# PIC32MZ1025DAG176 device description
Architecture: MIPS; Family: PIC32MZDA; Series: PIC32MZ
Registers are 32-bit, read-write, no defined reset value unless marked. A register's access mark holds for its fields unless they carry their own. Offsets are from the block's base; [hi:lo] are bit positions; {n}, {i} and the like mark numbered series; 'fields as' and 'values as' point back to an identical list.

## USB
Instances: USB 0x1f8e3000 in periph_indep
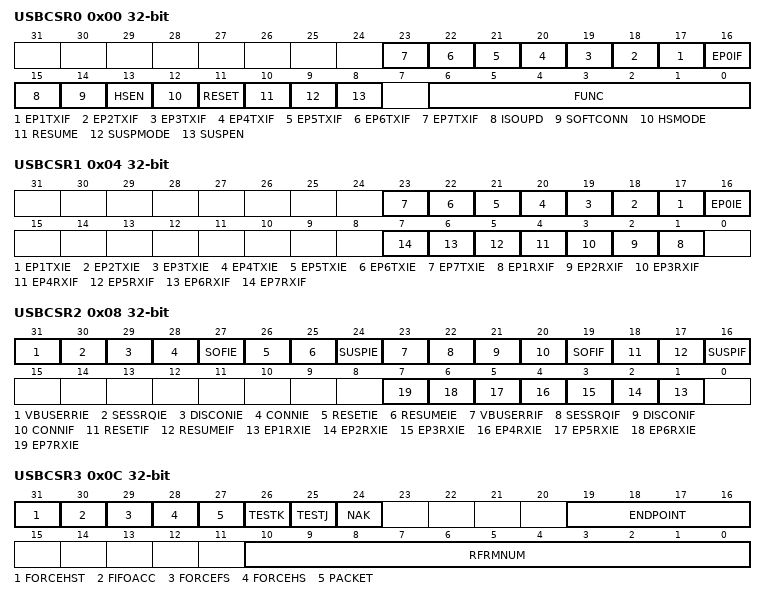
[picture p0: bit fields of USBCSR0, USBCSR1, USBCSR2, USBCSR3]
0x00 USBCSR0 — USB Control Status Register 0
  [n+16] EP{n}TXIF (n=1..7) — Endpoint {n} TX Interrupt Flag bit
    1=Endpoint has a transmit interrupt to be serviced; 0=No interrupt event
  [16] EP0IF — Endpoint 0 Interrupt bit
    1=Endpoint 0 has an interrupt to be serviced; 0=No interrupt event
  [15] ISOUPD — ISO Update bit (
    1=USB module will wait for a SOF token from the time TXPKTRDY is set before sending the packet; 0=No change in behavior
  [14] SOFTCONN — Soft Connect/Disconnect Feature Selection bit
    1=The USB D+/D- lines are enabled and active; 0=The USB D+/D- lines are disabled and are tri-stated
  [13] HSEN — Hi-Speed Enable bit
    1=The USB module will negotiate for Hi-Speed mode when the device is reset by the hub; 0=Module only operates in Full-Speed mode
  [12] HSMODE — Hi-Speed Mode Status bit
    1=Hi-Speed mode successfully negotiated during USB reset; 0=Module is not in Hi-Speed mode
  [11] RESET — Module Reset Status bit
    1=Reset signaling is present on the bus; 0=Normal module operation
  [10] RESUME — Resume from Suspend control bit
    1=Generate Resume signaling when the device is in Suspend mode; 0=Stop Resume signaling
  [9] SUSPMODE — Suspend Mode status bit
    1=The USB module is in Suspend mode; 0=The USB module is in Normal operations
  [8] SUSPEN — Suspend Mode Enable bit
    1=Suspend mode is enabled; 0=Suspend mode is not enabled
  [6:0] FUNC
0x04 USBCSR1 — USB Control Status Register 1
  [n+16] EP{n}TXIE (n=1..7) — Endpoint {n} Transmit Interrupt Enable bits
    1=Endpoint Transmit interrupt events are enabled; 0=Endpoint Transmit interrupt events are not enabled
  [16] EP0IE — Endpoint 0 Interrupt Enable bit
    1=Endpoint 0 interrupt events are enabled; 0=Endpoint 0 interrupt events are not enabled
  [n] EP{n}RXIF (n=1..7) — Endpoint {n} RX Interrupt bit
    1=Endpoint has a receive event to be serviced; 0=No interrupt event
0x08 USBCSR2 — USB Control Status Register 2
  [31] VBUSERRIE — Vbus Error Interrupt Enable bit
    1=Vbus error interrupt is enabled; 0=Vbus error interrupt is disabled
  [30] SESSRQIE — Session Request Interrupt Enable bit
    1=Session request interrupt is enabled; 0=Session request interrupt is disabled
  [29] DISCONIE — Device Disconnect Interrupt Enable bit
    1=Device disconnect interrupt is enabled; 0=Device disconnect interrupt is disabled
  [28] CONNIE — Device Connection Interrupt Enable bit
    1=Device connection interrupt is enabled; 0=Device connection interrupt is disabled
  [27] SOFIE — Start of Frame Interrupt Enable bit
    1=Start of Frame event interrupt is enabled; 0=Start of Frame event interrupt is disabled
  [26] RESETIE — Reset/Babble Interrupt Enable bit
    1=Interrupt when reset (; 0=Reset/Babble interrupt is disabled
  [25] RESUMEIE — Resume Interrupt Enable bit
    1=Resume signaling interrupt is enabled; 0=Resume signaling interrupt is disabled
  [24] SUSPIE — Suspend Interrupt Enable bit
    1=Suspend signaling interrupt is enabled; 0=Suspend signaling interrupt is disabled
  [23] VBUSERRIF — Vbus Error Interrupt bit
    1=Vbus has dropped below the Vbus valid threshold during a session; 0=No interrupt
  [22] SESSRQIF — Session Request Interrupt bit
    1=Session request signaling has been detected; 0=No session request detected
  [21] DISCONIF — Device Disconnect Interrupt bit
    1=In Host mode; 0=No device disconnect detected
  [20] CONNIF — Device Connection Interrupt bit
    1=In Host mode; 0=No device connection detected
  [19] SOFIF — Start of Frame Interrupt bit
    1=A new frame has started; 0=No start of frame detected
  [18] RESETIF — Reset/Babble Interrupt bit
    1=(In Host mode): indicates babble is detected / (In Device mode): indicates reset signaling is detected on the bus; 0=No reset/babble detected
  [17] RESUMEIF — Resume Interrupt bit
    1=Resume signaling is detected on the bus while USB module is in Suspend mode; 0=No Resume signaling detected
  [16] SUSPIF — Suspend Interrupt bit
    1=Suspend signaling is detected on the bus (Device mode); 0=No suspend signaling detected
  [n] EP{n}RXIE (n=1..7) — Endpoint {n} Receive Interrupt Enable bit
    1=Receive interrupt is enabled for this endpoint; 0=Receive interrupt is not enabled
0x0C USBCSR3 — USB Control Status Register 3
  [31] FORCEHST — Test Mode Force Host Select bit
    1=Forces USB module into Host mode; 0=Normal operation
  [30] FIFOACC — Test Mode Endpoint 0 FIFO Transfer Force bit
    1=Transfers the packet in the Endpoint 0 TX FIFO to the Endpoint 0 RX FIFO; 0=No transfer
  [29] FORCEFS — Test mode Force Full-Speed Mode Select bit
    1=Forces USB module into Full-Speed mode. Undefined behavior if FORCEHS is 1; 0=(If FORCEHS is 0): places USB module into Low-Speed mode
  [28] FORCEHS — Test mode Force Hi-Speed Mode Select bit
    1=Forces USB module into Hi-Speed mode. Undefined behavior if FORCEFS = 1.; 0=If FORCEFS is 0
  [27] PACKET — Test_Packet Test Mode Select bit
    1=The USB module repetitively transmits on the bus a 53-byte test packet. Test packet must be loaded into the Endpoint 0 FIFO before the test mode is entered.; 0=Normal operation
  [26] TESTK — Test_K Test Mode Select bit
    1=Enters Test_K test mode. The USB module transmits a continuous K on the bus.; 0=Normal operation
  [25] TESTJ — Test_J Test Mode Select bit
    1=Enters Test_J test mode. The USB module transmits a continuous J on the bus.; 0=Normal operation
  [24] NAK — Test_SE0_NAK Test Mode Select bit
    1=Enter Test_SE0_NAK test mode. The USB module remains in Hi-Speed mode but responds to any valid IN token with a NAK; 0=Normal operation
  [19:16] ENDPOINT — Endpoint Registers Select bits
    {v}=Endpoint {v} (v=0..7)
  [10:0] RFRMNUM
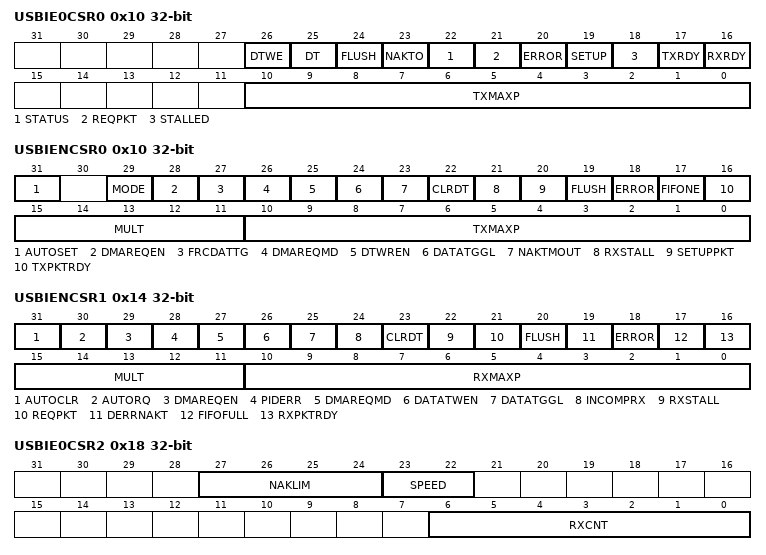
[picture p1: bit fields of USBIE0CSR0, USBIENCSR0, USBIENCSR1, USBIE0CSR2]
0x10 USBIE0CSR0 — USB Indexed Endpoint Control Status Register 0 (Endpoint 0)
  [26] DTWE, [25] DT, [24] FLUSH, [23] NAKTO, [22] STATUS, [21] REQPKT, [20] ERROR, [19] SETUP, [18] STALLED, [17] TXRDY, [16] RXRDY, [10:0] TXMAXP
0x10 USBIENCSR0 — USB Indexed Endpoint Control Status Register 0 (Endpoint 1-7)
  [31] AUTOSET — Auto Set Control bit
    1=TXPKTRDY will be automatically set when data of the maximum packet size (value in TXMAXP) is loaded into the TX FIFO. If a packet of less than the maximum packet size is loaded; 0=TXPKTRDY must be set manually for all packet sizes
  [29] MODE — Endpoint Direction Control bit
    1=Endpoint is TX; 0=Endpoint is RX
  [28] DMAREQEN — Endpoint DMA Request Enable bit
    1=DMA requests are enabled for this endpoint; 0=DMA requests are disabled for this endpoint
  [27] FRCDATTG — Force Endpoint Data Toggle Control bit
    1=Forces the endpoint data toggle to switch and the data packet to be cleared from the FIFO; 0=No forced behavior
  [26] DMAREQMD — Endpoint DMA Request Mode Control bit
    1=DMA Request Mode 1; 0=DMA Request Mode 0
  [25] DTWREN
  [24] DATATGGL
  [23] NAKTMOUT — Incomplete TX Status bit
    1=Meaning of bitfield depends on Host / Device mode of operation; 0=Meaning of bitfield depends on Host / Device mode of operation
  [22] CLRDT — Clear Data Toggle Control bit
    1=Resets the endpoint data toggle to 0; 0=Do not clear the data toggle
  [21] RXSTALL — STALL handshake transmission status bit
    values as NAKTMOUT
  [20] SETUPPKT — STALL handshake transmission control bit
    values as NAKTMOUT
  [19] FLUSH — FIFO Flush control bit
    1=Flush the latest packet from the endpoint TX FIFO. The FIFO pointer is reset; 0=Do not flush the FIFO
  [18] ERROR — Underrun status bit
    values as NAKTMOUT
  [17] FIFONE — FIFO Not Empty status bit
    1=There is at least 1 packet in the TX FIFO; 0=TX FIFO is empty
  [16] TXPKTRDY
  [15:11] MULT
  [10:0] TXMAXP
0x14 USBIENCSR1 — USB Indexed Endpoint Control Status Register 1 (Endpoint 1-7)
  [31] AUTOCLR — RXPKTRDY Automatic Clear Control bit
    1=RXPKTRDY will be automatically cleared when a packet of RXMAXP bytes has been unloaded from the RX FIFO. When packets of less than the maximum packet size are unloaded; 0=No automatic clearing of RXPKTRDY
  [30] AUTORQ — Isochronous Endpoint Control bit
    values as USBIENCSR0.NAKTMOUT
  [29] DMAREQEN — DMA Request Enable Control bit
    1=Enable DMA requests for the RX endpoint; 0=Disable DMA requests for the RX endpoint
  [28] PIDERR — Disable NYET Handshakes Control/PID Error Status bit
    values as USBIENCSR0.NAKTMOUT
  [27] DMAREQMD — DMA Request Mode Selection bit
    1=DMA Request Mode 1; 0=DMA Request Mode 0
  [26] DATATWEN — Data Toggle Write Enable Control bit (
    1=DATATGGL can be written; 0=DATATGGL is not writable
  [25] DATATGGL
  [24] INCOMPRX — Incomplete Packet Status bit
    1=The packet in the RX FIFO during a high-bandwidth Isochronous/Interrupt transfer is incomplete because parts of the data were not received; 0=Written by then software to clear this bit
  [23] CLRDT — Clear Data Toggle Control bit
    1=Reset the endpoint data toggle to 0; 0=Leave endpoint data toggle alone
  [22] RXSTALL — STALL Handshake Status bit
    values as USBIENCSR0.NAKTMOUT
  [21] REQPKT — STALL Handshake Control bit
    values as USBIENCSR0.NAKTMOUT
  [20] FLUSH — Flush FIFO Control bit
    1=Flush the next packet to be read from the endpoint RX FIFO. The FIFO pointer is reset and the RXPKTRDY bit is cleared. This should only be used when RXPKTRDY is set. If the FIFO is double-buffered; 0=Normal FIFO operation
  [19] DERRNAKT — Data Packet Error Status bit
    values as USBIENCSR0.NAKTMOUT
  [18] ERROR — Data Overrun Status bit
    values as USBIENCSR0.NAKTMOUT
  [17] FIFOFULL — FIFO Full Status bit
    1=No more packets can be loaded into the RX FIFO; 0=The RX FIFO has at least one free space
  [16] RXPKTRDY — Data Packet Reception Status bit
    1=A data packet has been received. An interrupt is generated.; 0=Written by software to clear this bit when the packet has been unloaded from the RX FIFO
  [15:11] MULT
  [10:0] RXMAXP
0x18 USBIE0CSR2 — USB Indexed Endpoint Control Status Register 2 (Endpoint 0)
  [27:24] NAKLIM
  [23:22] SPEED — Operating Speed Control bits
    3=Low-Speed; 2=Full-Speed; 1=Hi-Speed
  [6:0] RXCNT
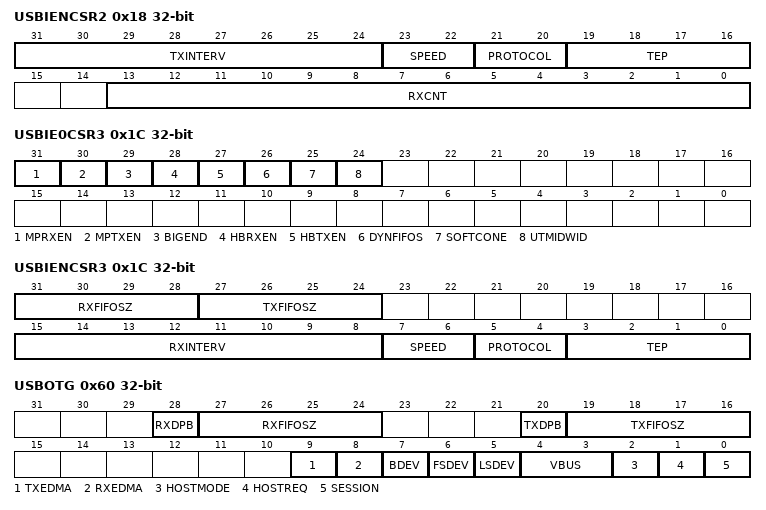
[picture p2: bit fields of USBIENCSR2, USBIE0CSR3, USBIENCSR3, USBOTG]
0x18 USBIENCSR2 — USB Indexed Endpoint Control Status Register 2 (Endpoint 1-7)
  [31:24] TXINTERV
  [23:22] SPEED — TX Endpoint Operating Speed Control bits (
    3=Low-Speed; 2=Full-Speed; 1=Hi-Speed
  [21:20] PROTOCOL — TX Endpoint Protocol Control bits
    3=Interrupt; 2=Bulk; 1=Isochronous; 0=Control
  [19:16] TEP
  [13:0] RXCNT
0x1C USBIE0CSR3 ro — USB Indexed Endpoint Control Status Register 3 (Endpoint 0)
  [31] MPRXEN — Automatic Amalgamation Option bit
    1=Automatic amalgamation of bulk packets is done; 0=No automatic amalgamation
  [30] MPTXEN — Automatic Splitting Option bit
    1=Automatic splitting of bulk packets is done; 0=No automatic splitting
  [29] BIGEND — Byte Ordering Option bit
    1=Big Endian ordering; 0=Little Endian ordering
  [28] HBRXEN — High-bandwidth RX ISO Option bit
    1=High-bandwidth RX ISO endpoint support is selected; 0=No High-bandwidth RX ISO support
  [27] HBTXEN — High-bandwidth TX ISO Option bit
    1=High-bandwidth TX ISO endpoint support is selected; 0=No High-bandwidth TX ISO support
  [26] DYNFIFOS — Dynamic FIFO Sizing Option bit
    1=Dynamic FIFO sizing is supported; 0=No Dynamic FIFO sizing
  [25] SOFTCONE — Soft Connect/Disconnect Option bit
    1=Soft Connect/Disconnect is supported; 0=Soft Connect/Disconnect is not supported
  [24] UTMIDWID
0x1C USBIENCSR3 — USB Indexed Endpoint Control Status Register 3 (Endpoint 1-7)
  [31:28] RXFIFOSZ — Receive FIFO Size bits
    13=8192 bytes; 12=4096 bytes; 11=2048 bytes; 10=1024 bytes; 9=512 bytes; 8=256 bytes; 7=128 bytes; 6=64 bytes; 5=32 bytes; 4=16 bytes; 3=8 bytes; 0=Reserved or endpoint has not been configured
  [27:24] TXFIFOSZ — Transmit FIFO Size bits
    values as RXFIFOSZ
  [15:8] RXINTERV
  [7:6] SPEED — RX Endpoint Operating Speed Control bits
    3=Low-Speed; 2=Full-Speed; 1=Hi-Speed
  [5:4] PROTOCOL — RX Endpoint Protocol Control bits
    3=Interrupt; 2=Bulk; 1=Isochronous; 0=Control
  [3:0] TEP
{0x20+4i} USBFIFO{i} (i=0..7) — USB FIFO Data Register x (x = 0-7
  [31:0] DATA
0x60 USBOTG — USB OTG Control/Status Register
  [28] RXDPB — RX Endpoint Double-packet Buffering Control bit
    1=Double-packet buffer is supported. This doubles the size set in RXFIFOSZ.; 0=Double-packet buffer is not supported
  [27:24] RXFIFOSZ — RX Endpoint FIFO Packet Size bits
    9=4096 bytes; 8=2048 bytes; 7=1024 bytes; 6=512 bytes; 5=256 bytes; 4=128 bytes; 3=64 bytes; 2=32 bytes; 1=16 bytes; 0=8 bytes
  [20] TXDPB — TX Endpoint Double-packet Buffering Control bit
    1=Double-packet buffer is supported. This doubles the size set in TXFIFOSZ.; 0=Double-packet buffer is not supported
  [19:16] TXFIFOSZ — TX Endpoint FIFO packet size bits
    values as RXFIFOSZ
  [9] TXEDMA — TX Endpoint DMA Assertion Control bit
    1=DMA_REQ signal for all IN endpoints will be deasserted when MAXP-8 bytes have been written to an endpoint. This is Early mode.; 0=DMA_REQ signal for all IN endpoints will be deasserted when MAXP bytes have been written to an endpoint. This is Late mode.
  [8] RXEDMA — RX Endpoint DMA Assertion Control bit
    1=DMA_REQ signal for all OUT endpoints will be deasserted when MAXP-8 bytes have been written to an endpoint. This is Early mode.; 0=DMA_REQ signal for all OUT endpoints will be deasserted when MAXP bytes have been written to an endpoint. This is Late mode.
  [7] BDEV — USB Device Type bit
    1=USB is operating as a B device; 0=USB is operating as an A device
  [6] FSDEV — Full-Speed/Hi-Speed device detection bit (
    1=A Full-Speed or Hi-Speed device has been detected being connected to the port; 0=No Full-Speed or Hi-Speed device detected
  [5] LSDEV — Low-Speed Device Detection bit
    1=A Low-Speed device has been detected being connected to the port; 0=No Low-Speed device detected
  [4:3] VBUS — Vbus Level Detection bits
    3=Above Vbus Valid; 2=Above AValid; 1=Above Session End; 0=Below Session End
  [2] HOSTMODE — Host Mode bit
    1=USB module is acting as a Host; 0=USB module is not acting as a Host
  [1] HOSTREQ — Host Request Control bit
    1=USB module initiates the Host Negotiation when Suspend mode is entered. This bit is cleared when Host Negotiation is completed.; 0=Host Negotiation is not taking place
  [0] SESSION — Active Session Control/Status bit
    1=(A device): Start a session / (B device): Session has started or is in progress; 0=(A device): End a session / (B device): When USB module is in Suspend mode
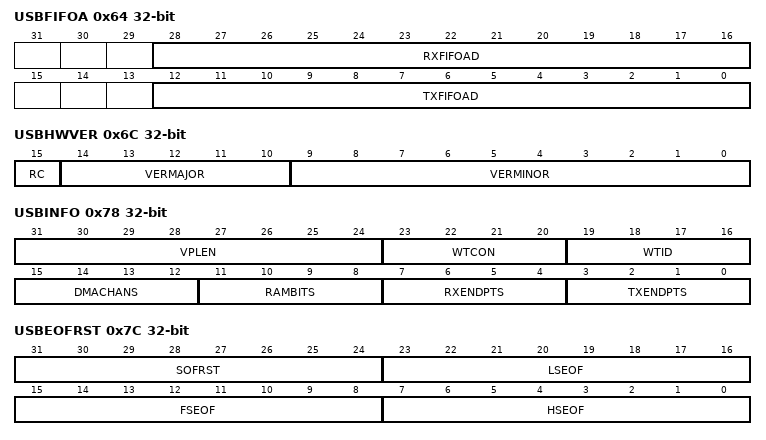
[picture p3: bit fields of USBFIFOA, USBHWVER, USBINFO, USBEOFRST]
0x64 USBFIFOA — USB FIFO Address Register
  [28:16] RXFIFOAD — Receive Endpoint FIFO Address bits
    0x1fff=0xFFF8; 2=0x0010; 1=0x0008; 0=0x0000
  [12:0] TXFIFOAD — Transmit Endpoint FIFO Address bits
    0x1fff=0xFFF8; 2=0x0010; 1=0x0008; 0=0x0000
0x6C USBHWVER ro — USB Hardware Version Register
  [15] RC — Release Candidate bit
    1=USB module was created using a release candidate; 0=USB module was created using a full release
  [14:10] VERMAJOR
  [9:0] VERMINOR
0x78 USBINFO — USB Information Register
  [31:24] VPLEN, [23:20] WTCON, [19:16] WTID, [15:12] DMACHANS, [11:8] RAMBITS, [7:4] RXENDPTS, [3:0] TXENDPTS
0x7C USBEOFRST — USB End-of-Frame/Soft Reset Control Register
  [31:24] SOFRST, [23:16] LSEOF, [15:8] FSEOF, [7:0] HSEOF
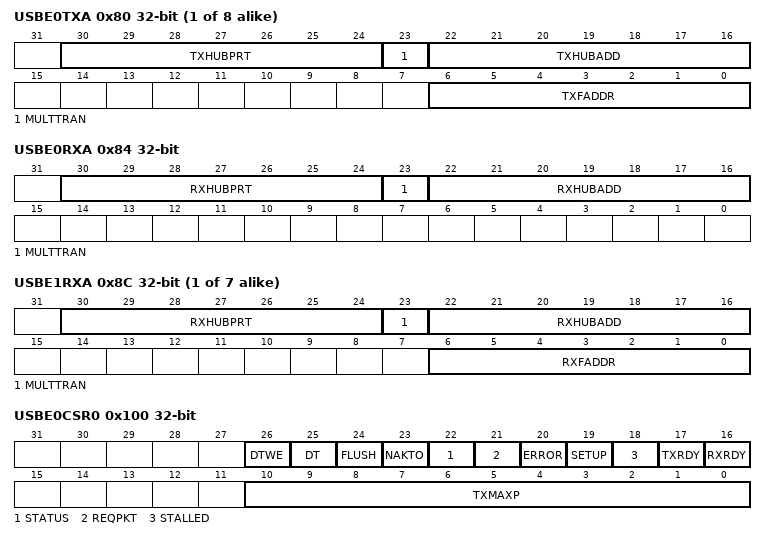
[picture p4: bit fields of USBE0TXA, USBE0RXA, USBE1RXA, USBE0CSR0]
{0x80+8i} USBE{i}TXA (i=0..7) — USB Endpoint {i} Transmit Address Register
  [30:24] TXHUBPRT
  [23] MULTTRAN — TX Hub Multiple Translators bit
    1=The USB 2.0 hub has multiple transaction translators; 0=The USB 2.0 hub has a single transaction translator
  [22:16] TXHUBADD
  [6:0] TXFADDR
0x84 USBE0RXA — USB Endpoint 0 Receive Address Register
  [30:24] RXHUBPRT
  [23] MULTTRAN — RX Hub Multiple Translators bit
    values as USBE0TXA.MULTTRAN
  [22:16] RXHUBADD
{0x84+8i} USBE{i}RXA (i=1..7) — USB Endpoint {i} Receive Address Register
  [30:24] RXHUBPRT
  [23] MULTTRAN — RX Hub Multiple Translators bit
    values as USBE0TXA.MULTTRAN
  [22:16] RXHUBADD
  [6:0] RXFADDR
0x100 USBE0CSR0
  fields as USBIE0CSR0
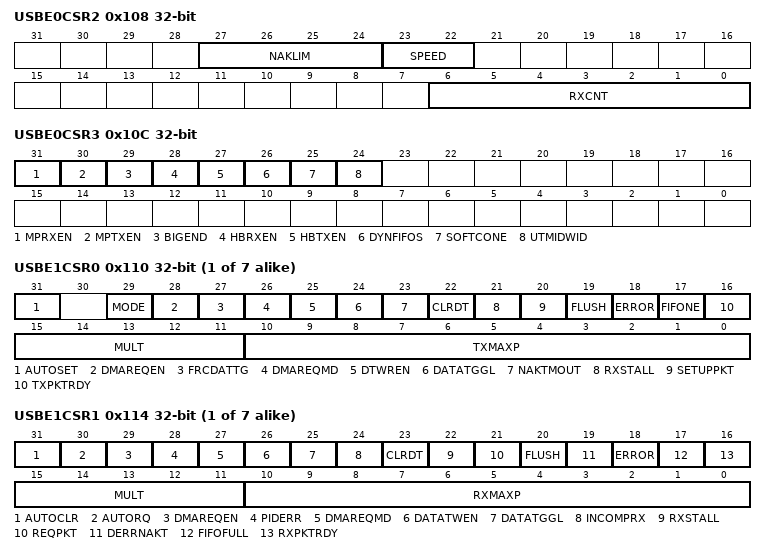
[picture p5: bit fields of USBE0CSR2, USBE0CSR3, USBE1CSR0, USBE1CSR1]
0x108 USBE0CSR2
  [27:24] NAKLIM, [23:22] SPEED, [6:0] RXCNT
0x10C USBE0CSR3
  [31] MPRXEN, [30] MPTXEN, [29] BIGEND, [28] HBRXEN, [27] HBTXEN, [26] DYNFIFOS, [25] SOFTCONE, [24] UTMIDWID
{0x100+0x10*i} USBE{i}CSR0 (i=1..7)
  [31] AUTOSET, [29] MODE, [28] DMAREQEN, [27] FRCDATTG, [26] DMAREQMD, [25] DTWREN, [24] DATATGGL, [23] NAKTMOUT, [22] CLRDT, [21] RXSTALL, [20] SETUPPKT, [19] FLUSH, [18] ERROR, [17] FIFONE, [16] TXPKTRDY, [15:11] MULT, [10:0] TXMAXP
{0x104+0x10*i} USBE{i}CSR1 (i=1..7)
  [31] AUTOCLR, [30] AUTORQ, [29] DMAREQEN, [28] PIDERR, [27] DMAREQMD, [26] DATATWEN, [25] DATATGGL, [24] INCOMPRX, [23] CLRDT, [22] RXSTALL, [21] REQPKT, [20] FLUSH, [19] DERRNAKT, [18] ERROR, [17] FIFOFULL, [16] RXPKTRDY, [15:11] MULT, [10:0] RXMAXP
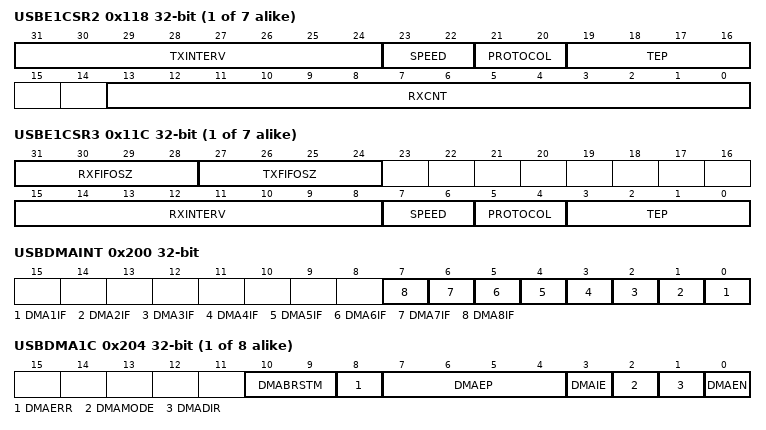
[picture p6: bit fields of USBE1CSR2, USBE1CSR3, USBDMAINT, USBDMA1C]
{0x108+0x10*i} USBE{i}CSR2 (i=1..7)
  [31:24] TXINTERV, [23:22] SPEED, [21:20] PROTOCOL, [19:16] TEP, [13:0] RXCNT
{0x10C+0x10*i} USBE{i}CSR3 (i=1..7)
  [31:28] RXFIFOSZ, [27:24] TXFIFOSZ, [15:8] RXINTERV, [7:6] SPEED, [5:4] PROTOCOL, [3:0] TEP
0x200 USBDMAINT — USB DMA Interrupt Register
  [all] fields
    1=The DMA channel has an interrupt event; 0=No interrupt event
  [n-1] DMA{n}IF (n=1..8) — DMA Channel {n} Interrupt bit
{0x1F4+0x10*i} USBDMA{i}C (i=1..8) — USB DMA Channel {i} Control Register
  [10:9] DMABRSTM — DMA Burst Mode Selection bit
    3=Burst Mode 3: INCR16; 2=Burst Mode 2: INCR8; 1=Burst Mode 1: INCR4 or unspecified length; 0=Burst Mode 0: Bursts of unspecified length
  [8] DMAERR — Bus Error bit
    1=A bus error has been observed on the input; 0=The software writes this to clear the error
  [7:4] DMAEP
  [3] DMAIE — DMA Interrupt Enable bit
    1=Interrupt is enabled for this channel; 0=Interrupt is disabled for this channel
  [2] DMAMODE — DMA Transfer Mode bit
    1=DMA Mode1 Transfers; 0=DMA Mode0 Transfers
  [1] DMADIR — DMA Transfer Direction bit
    1=DMA Read (TX endpoint); 0=DMA Write (RX endpoint)
  [0] DMAEN — DMA Enable bit
    1=Enable the DMA transfer and start the transfer; 0=Disable the DMA transfer
{0x1F8+0x10*i} USBDMA{i}A (i=1..8) — USB DMA Channel {i} Memory Address Register
  [31:0] DMAADDR
{0x1FC+0x10*i} USBDMA{i}N (i=1..8) — USB DMA Channel {i} Count Register
  [31:0] DMACOUNT
{0x300+4i} USBE{i}RPC (i=1..7) — USB Endpoint {i} Request Packet Count Register (Host Mode Only)
  [15:0] RQPKTCNT
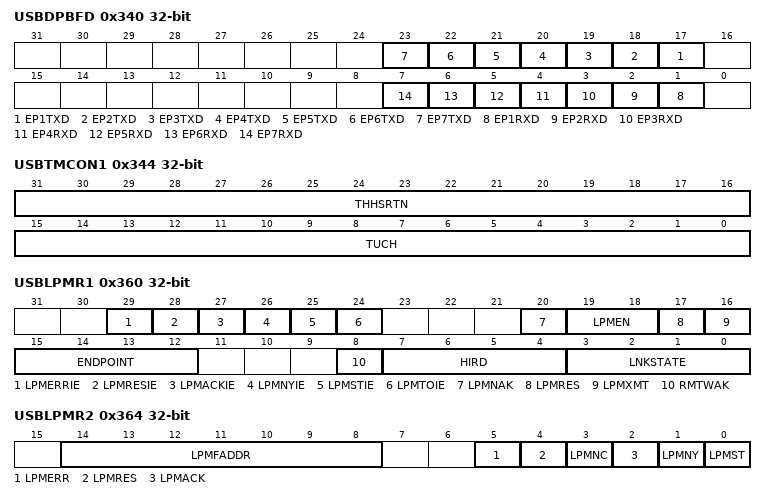
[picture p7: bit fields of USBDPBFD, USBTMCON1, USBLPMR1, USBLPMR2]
0x340 USBDPBFD — USB Double Packet Buffer Disable Register
  [n+16] EP{n}TXD (n=1..7) — TX Endpoint {n} Double Packet Buffer Disable bits
    1=TX double packet buffering is disabled for endpoint x; 0=TX double packet buffering is enabled for endpoint x
  [n] EP{n}RXD (n=1..7) — RX Endpoint {n} Double Packet Buffer Disable bits
    1=RX double packet buffering is disabled for endpoint x; 0=RX double packet buffering is enabled for endpoint x
0x344 USBTMCON1 — USB Timing Control Register 1
  [31:16] THHSRTN, [15:0] TUCH
0x348 USBTMCON2 — USB Timing Control Register 2
  [3:0] THSBT
0x360 USBLPMR1 — USB Link Power Management Control Register 1
  [29] LPMERRIE — LPM Error Interrupt Enable bit
    1=LPMERR interrupt is enabled; 0=LPMERR interrupt is disabled
  [28] LPMRESIE — LPM Resume Interrupt Enable bit
    1=LPMRES interrupt is enabled; 0=LPMRES interrupt is disabled
  [27] LPMACKIE — LPM Acknowledge Interrupt Enable bit
    1=Enable the LPMACK Interrupt; 0=Disable the LPMACK Interrupt
  [26] LPMNYIE — LPM NYET Interrupt Enable bit
    1=Enable the LPMNYET Interrupt; 0=Disable the LPMNYET Interrupt
  [25] LPMSTIE — LPM STALL Interrupt Enable bit
    1=Enable the LPMST Interrupt; 0=Disable the LPMST Interrupt
  [24] LPMTOIE — LPM Time-out Interrupt Enable bit
    1=Enable the LPMTO Interrupt; 0=Disable the LPMTO Interrupt
  [20] LPMNAK — LPM-only Transaction Setting bit
    1=All endpoints will respond to all transactions other than a LPM transaction with a NAK; 0=Normal transaction operation
  [19:18] LPMEN — LPM Enable bits (
    3=LPM Extended transactions are supported; 2=LPM and Extended transactions are not supported; 1=LPM mode is not supported but Extended transactions are supported; 0=LPM Extended transactions are supported
  [17] LPMRES — LPM Resume bit
    1=Initiate resume (remote wake-up). Resume signaling is asserted for 50 s.; 0=No resume operation
  [16] LPMXMT — LPM Transition to the L1 State bit
    1=(Device mode) USB module will transition to the L1 state upon the receipt of the next LPM transaction. LPMEN must be set to 0b11. Both LPMXMT and LPMEN must be set in the same cycle. / (Host mode)USB module will transmit an LPM transaction. This bit is self clearing; 0=(Device and host modes) Maintain current state
  [15:12] ENDPOINT
  [8] RMTWAK — Remote Wake-up Enable bit
    1=Remote wake-up is enabled; 0=Remote wake-up is disabled
  [7:4] HIRD
  [3:0] LNKSTATE
0x364 USBLPMR2 — USB Link Power Management Control Register 2
  [14:8] LPMFADDR, [5] LPMERR, [4] LPMRES, [3] LPMNC, [2] LPMACK, [1] LPMNY, [0] LPMST
Value list USBIENCSR0__ISO: 0x40000000=Enables the endpoint for Isochronous transfers; 0=Disables the endpoint for Isochronous transfers and enables it for Bulk or Interrupt transfers

## Notices in the file
Copyright (c) 2017 Microchip Technology Inc.
SPDX-License-Identifier: Apache-2.0
Licensed under the Apache License, Version 2.0 (the "License");
you may not use this file except in compliance with the License.
You may obtain a copy of the License at
http://www.apache.org/licenses/LICENSE-2.0
Unless required by applicable law or agreed to in writing, software
distributed under the License is distributed on an "AS IS" BASIS,
WITHOUT WARRANTIES OR CONDITIONS OF ANY KIND, either express or implied.
See the License for the specific language governing permissions and
limitations under the License.
